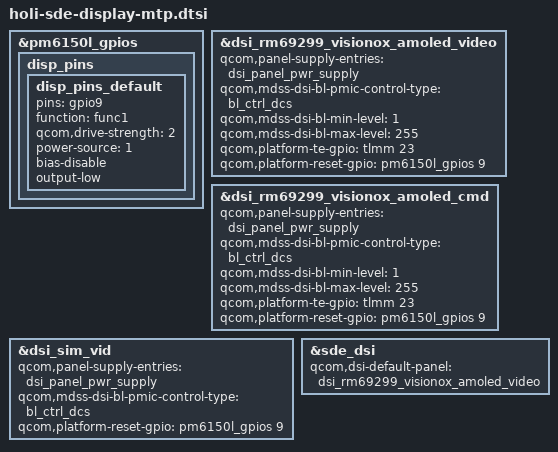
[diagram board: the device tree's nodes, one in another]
#include "holi-sde-display.dtsi"

&pm6150l_gpios {
	disp_pins {
		disp_pins_default: disp_pins_default {
			pins = "gpio9";
			function = "func1";
			qcom,drive-strength = <2>;
			power-source = <1>;
			bias-disable;
			output-low;
		};
	};
};

&dsi_rm69299_visionox_amoled_video {
	qcom,panel-supply-entries = <&dsi_panel_pwr_supply>;
	qcom,mdss-dsi-bl-pmic-control-type = "bl_ctrl_dcs";
	qcom,mdss-dsi-bl-min-level = <1>;
	qcom,mdss-dsi-bl-max-level = <255>;
	qcom,platform-te-gpio = <&tlmm 23 0>;
	qcom,platform-reset-gpio = <&pm6150l_gpios 9 0>;
};

&dsi_rm69299_visionox_amoled_cmd {
	qcom,panel-supply-entries = <&dsi_panel_pwr_supply>;
	qcom,mdss-dsi-bl-pmic-control-type = "bl_ctrl_dcs";
	qcom,mdss-dsi-bl-min-level = <1>;
	qcom,mdss-dsi-bl-max-level = <255>;
	qcom,platform-te-gpio = <&tlmm 23 0>;
	qcom,platform-reset-gpio = <&pm6150l_gpios 9 0>;
};

&dsi_sim_vid {
	qcom,panel-supply-entries = <&dsi_panel_pwr_supply>;
	qcom,mdss-dsi-bl-pmic-control-type = "bl_ctrl_dcs";
	qcom,platform-reset-gpio = <&pm6150l_gpios 9 0>;
};

&sde_dsi {
	qcom,dsi-default-panel = <&dsi_rm69299_visionox_amoled_video>;
};
